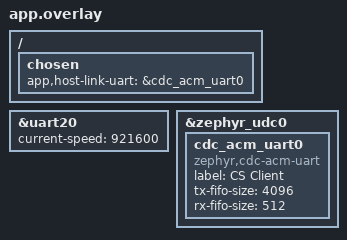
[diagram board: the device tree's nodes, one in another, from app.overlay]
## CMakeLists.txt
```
# SPDX-License-Identifier: MIT

cmake_minimum_required(VERSION 3.20.0)
set(CMAKE_EXPORT_COMPILE_COMMANDS ON)

# Avoid archive failures with the NCS toolchain's ccache link launcher.
set(USE_CCACHE 0)

# One source tree, two builds (README.md): prj.conf is the Bluetooth build,
# -DFILE_SUFFIX=radio_test uses prj_radio_test.conf instead. Both get the shared
# settings; Zephyr merges this with any EXTRA_CONF_FILE given on the command line.
list(APPEND EXTRA_CONF_FILE common.conf)

find_package(Zephyr REQUIRED HINTS $ENV{ZEPHYR_BASE})
project(cs_client)

if(NOT CONFIG_BT)
    set(APP_LIBS_RADIO_TEST ON)
endif()
include(${CMAKE_CURRENT_SOURCE_DIR}/../common/libs/libs.cmake)
target_link_libraries(app PRIVATE app_libs)

target_sources(app PRIVATE
    src/main.c
    src/client_state.c
)

if(CONFIG_BT)
    target_sources(app PRIVATE src/cs_session.c src/peer_discovery.c)
else()
    # The NCS radio test driver is used as-is; its shell front-end is not built.
    target_sources(app PRIVATE
        ${ZEPHYR_NRF_MODULE_DIR}/samples/peripheral/radio_test/src/radio_test.c
        src/radio_session.c
    )
endif()

# Keep the compilation database where clangd discovers it automatically.
add_custom_target(copy_compile_commands ALL
        COMMAND ${CMAKE_COMMAND} -E copy_if_different
                ${CMAKE_BINARY_DIR}/compile_commands.json
                ${CMAKE_CURRENT_SOURCE_DIR}/compile_commands.json
        DEPENDS zephyr_final
        COMMENT "Copying compile_commands.json for clangd"
)

# Export after HEX generation, including builds with no source changes. The
# radio test build (-DFILE_SUFFIX=radio_test) gets its own file name.
if(CONFIG_BUILD_OUTPUT_HEX)
    set(CS_HEX_EXPORT_DIR "${CMAKE_CURRENT_SOURCE_DIR}/../bin")
    set(CS_HEX_EXPORT_NAME "${PROJECT_NAME}")
    if(FILE_SUFFIX)
        string(APPEND CS_HEX_EXPORT_NAME "_${FILE_SUFFIX}")
    endif()
    set(CS_HEX_EXPORT_FILE "${CS_HEX_EXPORT_DIR}/${CS_HEX_EXPORT_NAME}_${BOARD}.hex")
    add_custom_target(cs_export_hex ALL
        COMMAND ${CMAKE_COMMAND} -E make_directory "${CS_HEX_EXPORT_DIR}"
        COMMAND ${CMAKE_COMMAND} -E copy
                "${BYPRODUCT_KERNEL_HEX_NAME}" "${CS_HEX_EXPORT_FILE}"
        DEPENDS "${BYPRODUCT_KERNEL_HEX_NAME}"
        COMMENT "Exporting firmware HEX to ${CS_HEX_EXPORT_FILE}"
        VERBATIM
    )
    add_dependencies(cs_export_hex ${logical_target_for_zephyr_elf})
endif()
```

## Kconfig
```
#
# SPDX-License-Identifier: MIT
#

mainmenu "CS protocol client"

rsource "../common/libs/Kconfig"

# Consumed unconditionally by the NCS radio_test.c in the radio test build,
# which does not build the sample's shell front-end that normally declares it.
config RADIO_TEST_RX_TIMEOUT
	int "RX packet reception timeout"
	depends on !BT
	default 10
	help
	  Time in seconds the driver waits for the first packet in RX mode when a
	  finite packet count is requested. The radio is disabled if it elapses.

config CS_CLIENT_RADIO_TEST_STATS_INTERVAL_MS
	int "RADIO_TEST_STATS report interval in milliseconds"
	depends on !BT
	range 50 10000
	default 250
	help
	  Period of the receive statistics reports while an RX or RX sweep
	  test runs. A baseline follows the START response and a final report
	  precedes the STOPPED state.

source "Kconfig.zephyr"
```

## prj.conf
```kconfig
# Bluetooth build (default): CS initiator and CS reflector in one image, the
# role chosen by the host at runtime, with both Ranging Service roles for
# real-time ranging data. Settings shared with the radio
# test build are in common.conf. Where the NCS ras_initiator and ras_reflector
# samples differ, the larger value is used.

# Host link on native USB CDC ACM (app.overlay), enabled without waiting for a
# host; DTR tracks the host port (CONFIG_APP_HOST_LINK_DTR follows the class).
CONFIG_USB_DEVICE_STACK_NEXT=y
CONFIG_CDC_ACM_SERIAL_INITIALIZE_AT_BOOT=y
CONFIG_CDC_ACM_SERIAL_ENABLE_AT_BOOT=y
CONFIG_CDC_ACM_SERIAL_PRODUCT_STRING="CS Client"
CONFIG_USBD_CDC_ACM_BUF_POOL=y
CONFIG_USBD_CDC_ACM_WORKQUEUE=y

CONFIG_BT=y
CONFIG_BT_DEVICE_NAME="CS Client"
CONFIG_BT_DEVICE_NAME_DYNAMIC=y
CONFIG_BT_DEVICE_NAME_MAX=32
CONFIG_BT_MAX_CONN=1
# GAP role follows the configuration: central scans, peripheral advertises.
CONFIG_BT_CENTRAL=y
CONFIG_BT_PERIPHERAL=y
CONFIG_BT_SMP=y
# Pair for link encryption only; CS security needs no stored bond.
CONFIG_BT_BONDABLE=n
# Connection parameters come from the applied configuration.
CONFIG_BT_GAP_AUTO_UPDATE_CONN_PARAMS=n
CONFIG_BT_GATT_CLIENT=y
# Start the ATT MTU exchange on connection, as cs_hostless_initiator does: without it a
# hosted link stays at the ATT default 23 and the RAS responder segments the ranging data
# into ~39 notifications per procedure instead of 2 (§12.4).
CONFIG_BT_GATT_AUTO_UPDATE_MTU=y
CONFIG_BT_GATT_DYNAMIC_DB=y

CONFIG_BT_CHANNEL_SOUNDING=y
CONFIG_BT_CHANNEL_SOUNDING_TEST=n
# Lets CS and ACL use different PHYs.
CONFIG_BT_TRANSMIT_POWER_CONTROL=y

# The Ranging Profile recommends an ATT MTU of at least 247 octets.
CONFIG_BT_L2CAP_TX_MTU=498
CONFIG_BT_BUF_ACL_TX_SIZE=502
CONFIG_BT_BUF_ACL_RX_SIZE=502
CONFIG_BT_ATT_PREPARE_COUNT=3
CONFIG_BT_CTLR_DATA_LENGTH_MAX=251
CONFIG_BT_CTLR_PHY_2M=y

# Ranging Service: responder (CS reflector role) and requestor (CS initiator role).
CONFIG_BT_RAS=y
CONFIG_BT_RAS_MODE_3_SUPPORTED=y
CONFIG_BT_RAS_MAX_ANTENNA_PATHS=4
CONFIG_BT_RAS_RRSP=y
# The RRSP instance is allocated only in the reflector role.
CONFIG_BT_RAS_RRSP_AUTO_ALLOC_INSTANCE=n
CONFIG_BT_RAS_RRSP_MAX_ACTIVE_CONN=1
CONFIG_BT_RAS_RRSP_RD_BUFFERS_PER_CONN=1
CONFIG_BT_RAS_RREQ=y
CONFIG_BT_RAS_RREQ_MAX_ACTIVE_CONN=1

# SoftDevice Controller with both CS roles, mode 3 and up to 4 antenna paths.
# One local antenna on the DK; the paths come from a multi-antenna peer.
CONFIG_BT_CTLR_CHANNEL_SOUNDING=y
CONFIG_BT_CTLR_CHANNEL_SOUNDING_TEST=n
CONFIG_BT_CTLR_SDC_CS_ROLE_BOTH=y
CONFIG_BT_CTLR_SDC_CS_STEP_MODE3=y
CONFIG_BT_CTLR_SDC_CS_MAX_ANTENNA_PATHS=4
CONFIG_BT_CTLR_SDC_CS_NUM_ANTENNAS=1
# CS enhancements such as IPT need the LL Extended Feature Set.
CONFIG_BT_CTLR_EXTENDED_FEAT_SET=y

# Carry the complete configured name in extended advertising.
CONFIG_BT_EXT_ADV=y
CONFIG_BT_CTLR_ADV_DATA_LEN_MAX=64
CONFIG_BT_EXT_SCAN_BUF_SIZE=1650
# Connection, CS and RAS sequencing in both roles (common/libs/cs_roles).
CONFIG_APP_CS_ROLES=y
CONFIG_APP_CS_ROLES_INITIATOR=y
CONFIG_APP_CS_ROLES_REFLECTOR=y
```

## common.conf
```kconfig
# CS protocol client, settings shared by both builds; CMakeLists.txt adds this
# file to prj.conf or prj_radio_test.conf. Protocol frames on USB CDC ACM
# (Bluetooth build) or uart30 (radio test build), logs on the debug UART. See
# README.md.

CONFIG_APP_HOST_LINK=y
CONFIG_ASSERT=y
CONFIG_MAIN_STACK_SIZE=2048
# State changes raised from work items format their log message on the system work queue.
CONFIG_SYSTEM_WORKQUEUE_STACK_SIZE=2048

# Console on the debug UART; never mixed into the protocol stream. The app_log
# console consumer uses printk, which LOG_PRINTK passes through the deferred
# log with the Zephyr subsystem messages. Levels are set by SET_LOG_CONFIG.
CONFIG_CONSOLE=y
CONFIG_UART_CONSOLE=y
CONFIG_PRINTK=y
CONFIG_LOG=y
CONFIG_LOG_PRINTK=y
CONFIG_LOG_MODE_DEFERRED=y
CONFIG_LOG_PROCESS_THREAD=y
CONFIG_LOG_BUFFER_SIZE=2048
CONFIG_LOG_BACKEND_UART=y
CONFIG_LOG_BACKEND_UART_ASYNC=y
CONFIG_LOG_BACKEND_UART_BUFFER_SIZE=256

# The host link UART needs the interrupt API, but uart20 uses asynchronous UARTE DMA.
CONFIG_UART_ASYNC_API=y
CONFIG_UART_20_INTERRUPT_DRIVEN=n
CONFIG_UART_20_ASYNC=y
CONFIG_BOOT_BANNER=n
```

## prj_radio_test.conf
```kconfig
# Radio test build: direct radio access, no Bluetooth stack and no MPSL.
# Used instead of prj.conf with -DFILE_SUFFIX=radio_test; settings shared with
# the Bluetooth build are in common.conf. See README.md.
CONFIG_BT=n

# Host link on uart30 (app_radio_test.overlay), not USB: no USB device stack.
# A hardware UART has no DTR, so a host session ends only with CLOSE_SESSION.
CONFIG_UART_30_INTERRUPT_DRIVEN=y

CONFIG_DYNAMIC_INTERRUPTS=y
CONFIG_NRFX_TIMER=y
CONFIG_NRFX_GPPI=y
CONFIG_CLOCK_CONTROL=y

# radio_test.c seeds its transmit pattern from the entropy driver.
CONFIG_ENTROPY_GENERATOR=y
CONFIG_PSA_CRYPTO=y

# Provides <fem_al/fem_al.h>, which radio_test.h includes unconditionally.
# CONFIG_FEM stays off on a bare DK, so no FEM code is built.
CONFIG_FEM_AL_LIB=y
```

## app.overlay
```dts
/* SPDX-License-Identifier: MIT */
/ {
	chosen {
		app,host-link-uart = &cdc_acm_uart0;
	};
};

&uart20 {
	current-speed = <921600>;
};

&zephyr_udc0 {
	status = "okay";

	cdc_acm_uart0: cdc_acm_uart0 {
		compatible = "zephyr,cdc-acm-uart";
		label = "CS Client";
		tx-fifo-size = <4096>;
		rx-fifo-size = <512>;
	};
};
```

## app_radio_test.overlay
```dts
/* SPDX-License-Identifier: MIT */
/* Radio test build (-DFILE_SUFFIX=radio_test, used instead of app.overlay):
 * protocol frames on uart30, the DK's second virtual COM port, so the build
 * needs no USB device controller. Logs stay on uart20.
 */
/ {
	chosen {
		app,host-link-uart = &uart30;
	};
};

&uart20 {
	current-speed = <921600>;
};

&uart30 {
	status = "okay";
	current-speed = <921600>;
	hw-flow-control;
};
```

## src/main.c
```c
/* SPDX-License-Identifier: MIT */
#include <app_version.h>
#include <zephyr/kernel.h>

#include "app_log/app_log.h"
#include "host_link/host_link.h"
#include "session.h"

APP_LOG_MODULE(cs_client);

int main(void) {
	int err;

	APP_LOG_INF("CS client %s, %s build", APP_VERSION_STRING, session_build_name());

	/* Boots to IDLE: no radio activity before APPLY_CONFIG and START. */
	err = session_init();
	if (err) {
		APP_LOG_ERR("Session init failed: %d", err);
		return 0;
	}

	err = host_link_init(session_handlers());
	if (err) {
		APP_LOG_ERR("Host link init failed: %d", err);
		return 0;
	}
	APP_LOG_INF("Waiting for the host on USB CDC ACM");
	return 0;
}
```

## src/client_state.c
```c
/* SPDX-License-Identifier: MIT */
#include <zephyr/kernel.h>

#include "app_log/app_log.h"
#include "client_state.h"
#include "cs_protocol/cs_protocol_packets.h"
#include "host_link/host_link_names.h"
#include "host_link/host_link_reports.h"

APP_LOG_MODULE(client_state);

static K_MUTEX_DEFINE(lock);
static uint8_t state = CS_PROTOCOL_CLIENT_STATE_IDLE;
static uint8_t mode = CS_PROTOCOL_MODE_NONE;

/* Last change with an error the host has not received, sent after the next CONNECT. */
static struct {
	bool pending;
	uint8_t state;
	uint8_t mode;
	uint8_t reason;
	uint8_t hci_status;
	int32_t error;
} undelivered;

uint8_t client_state_get(void) {
	uint8_t value;

	k_mutex_lock(&lock, K_FOREVER);
	value = state;
	k_mutex_unlock(&lock);
	return value;
}

uint8_t client_state_mode(void) {
	uint8_t value;

	k_mutex_lock(&lock, K_FOREVER);
	value = mode;
	k_mutex_unlock(&lock);
	return value;
}

void client_state_set_mode(uint8_t new_mode) {
	k_mutex_lock(&lock, K_FOREVER);
	mode = new_mode;
	k_mutex_unlock(&lock);
}

/* States the host should treat as abnormal. */
static bool is_abnormal(uint8_t value, int32_t error) {
	return value == CS_PROTOCOL_CLIENT_STATE_LINK_LOST || value == CS_PROTOCOL_CLIENT_STATE_ERROR ||
	       error != 0;
}

/* Called with the lock held. */
static void set_locked(uint8_t new_state, uint8_t reason, uint8_t hci_status, int32_t error) {
	uint8_t old_state = state;
	int err;

	state = new_state;
	/* Without a host session the report is dropped and CONNECT reports the state;
	 * an error is kept so the host still learns why the operation ended.
	 */
	err = host_link_report_client_state(new_state, mode, reason, hci_status, error);
	if (error != 0) {
		undelivered.pending = err != 0;
		undelivered.state = new_state;
		undelivered.mode = mode;
		undelivered.reason = reason;
		undelivered.hci_status = hci_status;
		undelivered.error = error;
	} else if (err == 0) {
		/* The host has seen a newer state; an older interruption is stale. */
		undelivered.pending = false;
	}
	if (is_abnormal(new_state, error)) {
		APP_LOG_WRN("State %s -> %s, mode %s, reason %s, HCI status 0x%02x, error %d",
		            host_link_state_name(old_state), host_link_state_name(new_state),
		            host_link_mode_name(mode), host_link_reason_name(reason), hci_status,
		            (int)error);
	} else {
		APP_LOG_INF("State %s -> %s, mode %s, reason %s, HCI status 0x%02x",
		            host_link_state_name(old_state), host_link_state_name(new_state),
		            host_link_mode_name(mode), host_link_reason_name(reason), hci_status);
	}
}

void client_state_set(uint8_t new_state, uint8_t reason, uint8_t hci_status, int32_t error) {
	k_mutex_lock(&lock, K_FOREVER);
	set_locked(new_state, reason, hci_status, error);
	k_mutex_unlock(&lock);
}

bool client_state_change(uint8_t from, uint8_t to, uint8_t reason, int32_t error) {
	bool changed;

	k_mutex_lock(&lock, K_FOREVER);
	changed = state == from;
	if (changed) {
		set_locked(to, reason, 0U, error);
	}
	k_mutex_unlock(&lock);
	return changed;
}

void client_state_session_changed(bool active) {
	if (!active) {
		/* State and mode describe the device, not the host connection. */
		return;
	}
	k_mutex_lock(&lock, K_FOREVER);
	if (undelivered.pending &&
	    host_link_report_client_state(undelivered.state, undelivered.mode, undelivered.reason,
	                                  undelivered.hci_status, undelivered.error) == 0) {
		undelivered.pending = false;
		APP_LOG_WRN("Reported earlier state %s, reason %s, error %d",
		            host_link_state_name(undelivered.state),
		            host_link_reason_name(undelivered.reason), (int)undelivered.error);
	}
	k_mutex_unlock(&lock);
}
```

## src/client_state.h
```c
/* SPDX-License-Identifier: MIT */
#ifndef CLIENT_STATE_H_
#define CLIENT_STATE_H_

#include <stdbool.h>
#include <stdint.h>

/**
 * @file
 * @brief Client state and applied operation mode, reported as CLIENT_STATE.
 *
 * Thread context only. Every change is reported to the host while holding the
 * state lock, so the host sees changes in the order they happened: a
 * CLIENT_STATE frame followed by a LOG_MESSAGE naming the old and new state
 * (level warning for LINK_LOST, ERROR and any change with an error).
 *
 * A change with a non-zero error that could not be reported (no host session)
 * is reported again when the next session opens, unless the host has seen a
 * newer state in between.
 */

/** @brief Current @ref cs_protocol_client_state. */
uint8_t client_state_get(void);

/** @brief Applied operation mode, or @ref CS_PROTOCOL_MODE_NONE. */
uint8_t client_state_mode(void);

/** @brief Record the applied operation mode; no report. */
void client_state_set_mode(uint8_t mode);

/**
 * @brief Change the state and report it.
 *
 * @param state      One of @ref cs_protocol_client_state.
 * @param reason     One of @ref cs_protocol_reject_reason.
 * @param hci_status HCI status behind the change; 0 when none.
 * @param error      Negative errno when an operation ended abnormally; 0 otherwise.
 */
void client_state_set(uint8_t state, uint8_t reason, uint8_t hci_status, int32_t error);

/**
 * @brief Change the state and report it only if it is still @p from.
 * @return True when the state changed.
 */
bool client_state_change(uint8_t from, uint8_t to, uint8_t reason, int32_t error);

/**
 * @brief host_link session_changed handler: on open, report an undelivered
 * change with an error; ending a session preserves device state and mode.
 */
void client_state_session_changed(bool active);

#endif /* CLIENT_STATE_H_ */
```

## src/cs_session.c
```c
/* SPDX-License-Identifier: MIT */
/* Bluetooth build: host link handlers -> CS initiator / reflector roles. */
#include <app_version.h>
#include <errno.h>
#include <string.h>
#include <zephyr/bluetooth/bluetooth.h>
#include <zephyr/kernel.h>

#include "app_log/app_log.h"
#include "client_state.h"
#include "cs_roles/cs_role.h"
#include "cs_utils/cs_config.h"
#include "host_link/host_link.h"
#include "host_link/host_link_config.h"
#include "host_link/host_link_reports.h"
#include "peer_discovery.h"
#include "session.h"

APP_LOG_MODULE(cs_session);

/* Records of the applied configuration, converted with the cs_utils setters. */
static struct cs_initiator_config initiator;
static struct cs_reflector_config reflector;
static uint8_t gap_role;

/* The link layer owns the negotiated values; retain the latest snapshot so a
 * host that opens USB after Bluetooth connection setup still receives them. */
static struct k_spinlock connection_params_lock;
static struct cs_config_connection connection_params;
static uint16_t connection_mtu;
static bool connection_params_valid;

static void report_connection_params_work(struct k_work *work);
static K_WORK_DEFINE(connection_params_report_work,
                     report_connection_params_work);

static void role_connection_params(const struct cs_config_connection *params,
                                   uint16_t mtu) {
	if (!params) {
		return;
	}
	K_SPINLOCK(&connection_params_lock) {
		connection_params = *params;
		connection_mtu = mtu;
		connection_params_valid = true;
	}
	(void)k_work_submit(&connection_params_report_work);
}

static void report_connection_params_work(struct k_work *work) {
	struct cs_config_connection params;
	uint16_t mtu = 0;
	bool valid = false;

	ARG_UNUSED(work);
	if (!host_link_session_active()) {
		return;
	}
	K_SPINLOCK(&connection_params_lock) {
		params = connection_params;
		mtu = connection_mtu;
		valid = connection_params_valid;
	}
	if (valid) {
		(void)host_link_report_connection_parameters(params.interval_min,
		                                             params.latency,
		                                             params.timeout,
		                                             mtu);
	}
}

static uint8_t get_state(void) {
	return client_state_get();
}

/* Discovery and connection establishment are separate from CS START. */
static bool link_active(void) {
	return peer_discovery_active();
}

static const char *peer_data_name(uint8_t peer_data) {
	return peer_data == CS_CONFIG_PEER_DATA_NONE ? "none (initiator only)" : "RAS real-time";
}

static int convert(uint8_t mode,
                   const uint8_t *payload,
                   size_t len,
                   struct cs_initiator_config *initiator_out,
                   struct cs_reflector_config *reflector_out) {
	switch (mode) {
	case CS_PROTOCOL_MODE_CS_INITIATOR:
		return host_link_config_to_initiator(payload, len, initiator_out);
	case CS_PROTOCOL_MODE_CS_REFLECTOR:
		return host_link_config_to_reflector(payload, len, reflector_out);
	default:
		return -ENOTSUP;
	}
}

static struct host_link_result validate_config(uint8_t mode,
                                               const uint8_t *payload,
                                               size_t len) {
	struct cs_initiator_config initiator_check;
	struct cs_reflector_config reflector_check;
	int err = convert(mode, payload, len, &initiator_check, &reflector_check);

	if (err == -ENOTSUP) {
		return HOST_LINK_RESULT(CS_PROTOCOL_STATUS_UNSUPPORTED, CS_PROTOCOL_REASON_NONE);
	}
	return err ? HOST_LINK_RESULT_OUT_OF_RANGE(err) : HOST_LINK_RESULT_OK;
}

static struct host_link_result apply(const struct host_link_config_set *set) {
	struct cs_initiator_config initiator_new;
	struct cs_reflector_config reflector_new;
	/* The initiator record also takes SET_PEER_DATA, checked against the IPT request. */
	int err = set->mode == CS_PROTOCOL_MODE_CS_INITIATOR
	                  ? host_link_config_set_to_initiator(set, &initiator_new)
	                  : convert(set->mode, set->config, set->config_len, &initiator_new, &reflector_new);

	if (err) {
		return HOST_LINK_RESULT_OUT_OF_RANGE(err);
	}
	char device_name[33] = CONFIG_BT_DEVICE_NAME;
	if (set->has_device_name) {
		memcpy(device_name, &set->device_name[1], set->device_name[0]);
		device_name[set->device_name[0]] = '\0';
	}
	err = bt_set_name(device_name);
	if (err) {
		return HOST_LINK_RESULT_FAILED(err);
	}
	if (set->mode == CS_PROTOCOL_MODE_CS_INITIATOR) {
		initiator = initiator_new;
	} else {
		reflector = reflector_new;
	}
	gap_role = host_link_config_gap_role(set->config);
	peer_discovery_configure(gap_role,
	                         set->mode,
	                         set->mode == CS_PROTOCOL_MODE_CS_INITIATOR ? &initiator.connection
	                                                                    : &reflector.connection);

	APP_LOG_INF("CS %s, GAP %s, config ID %u%s",
	            set->mode == CS_PROTOCOL_MODE_CS_INITIATOR ? "initiator" : "reflector",
	            gap_role == CS_PROTOCOL_GAP_CENTRAL ? "central" : "peripheral",
	            set->mode == CS_PROTOCOL_MODE_CS_INITIATOR ? initiator.config_id : reflector.config_id,
	            set->has_patterns ? ", with peripheral patterns" : "");
	if (set->mode == CS_PROTOCOL_MODE_CS_INITIATOR) {
		APP_LOG_INF("Reflector data: %s, preferred T_PM %u us",
		            peer_data_name(initiator.peer_data),
		            initiator.t_pm_us);
	}
	client_state_set_mode(set->mode);
	client_state_set(CS_PROTOCOL_CLIENT_STATE_CONFIGURED, CS_PROTOCOL_REASON_NONE, 0U, 0);
	return HOST_LINK_RESULT_OK;
}

static struct host_link_result start(const struct host_link_config_set *set) {
	ARG_UNUSED(set);
	int err = client_state_mode() == CS_PROTOCOL_MODE_CS_INITIATOR ? cs_role_start_initiator(&initiator)
	                                                               : cs_role_start_reflector(&reflector);
	if (err == -ENOTCONN) {
		return HOST_LINK_RESULT(CS_PROTOCOL_STATUS_BAD_STATE, CS_PROTOCOL_REASON_CONNECT_FAILED);
	}
	return err ? HOST_LINK_RESULT_FAILED(err) : HOST_LINK_RESULT_OK;
}

/* STOP disables procedures and keeps the link. The initiator also waits for the
 * reflector's data of the last procedure: when it does not arrive, RAS_DATA_LOST
 * has been sent and the response is OK with CS_PROTOCOL_REASON_STOP_TIMEOUT.
 * The host link also calls this at session end: it cancels discovery or a CS
 * setup, and does nothing on an idle link. The role and event threads run above
 * the host link thread, so the STOPPED report of a cancelled setup has been
 * attempted, and kept for the next session, by the time cs_role_stop() returns.
 */
static struct host_link_result stop(void) {
	if (client_state_get() == CS_PROTOCOL_CLIENT_STATE_SCANNING ||
	    client_state_get() == CS_PROTOCOL_CLIENT_STATE_ADVERTISING ||
	    client_state_get() == CS_PROTOCOL_CLIENT_STATE_LINK_CONNECTING) {
		return peer_discovery_stop();
	}
	int err = cs_role_stop();
	if (err == -ETIMEDOUT) {
		return (struct host_link_result){ CS_PROTOCOL_STATUS_OK, CS_PROTOCOL_REASON_STOP_TIMEOUT, err };
	}
	return err ? HOST_LINK_RESULT_FAILED(err) : HOST_LINK_RESULT_OK;
}

static void interrupt(int error) {
	cs_role_interrupt(error);
}

/* Also called while RUNNING: procedures are stopped first, reported as a STOP. */
static struct host_link_result link_disconnect(void) {
	int err = cs_role_stop();
	if (err && err != -ETIMEDOUT && err != -ENOTCONN) {
		return HOST_LINK_RESULT_FAILED(err);
	}
	return peer_discovery_stop();
}

static uint8_t failure_reason(enum cs_role_failure_stage stage) {
	switch (stage) {
	case CS_ROLE_FAILURE_CONNECT:
		return CS_PROTOCOL_REASON_CONNECT_FAILED;
	case CS_ROLE_FAILURE_LINK_SECURITY:
		return CS_PROTOCOL_REASON_SECURITY_FAILED;
	case CS_ROLE_FAILURE_RAS_DISCOVERY:
		return CS_PROTOCOL_REASON_RAS_DISCOVERY_FAILED;
	case CS_ROLE_FAILURE_RAS_NO_REALTIME:
		return CS_PROTOCOL_REASON_RAS_NO_REALTIME;
	case CS_ROLE_FAILURE_SECURITY:
		return CS_PROTOCOL_REASON_CS_SECURITY_FAILED;
	case CS_ROLE_FAILURE_CAPABILITIES:
	case CS_ROLE_FAILURE_CONFIG:
	case CS_ROLE_FAILURE_PROCEDURE:
	case CS_ROLE_FAILURE_PEER_ANTENNA:
		return CS_PROTOCOL_REASON_CS_CONFIG_FAILED;
	case CS_ROLE_FAILURE_PEER_IPT:
		return CS_PROTOCOL_REASON_PEER_IPT_UNSUPPORTED;
	default:
		return CS_PROTOCOL_REASON_NONE;
	}
}

static void role_state(enum cs_role_state state,
                       enum cs_role_failure_stage stage,
                       enum cs_role_stop_reason stop_reason,
                       uint8_t hci_status,
                       int error) {
	switch (state) {
	case CS_ROLE_STATE_LINK_CONNECTED:
		client_state_set(CS_PROTOCOL_CLIENT_STATE_LINK_CONNECTED, CS_PROTOCOL_REASON_NONE, 0, 0);
		break;
	case CS_ROLE_STATE_LINK_ENCRYPTED:
		APP_LOG_INF("Peer link encrypted");
		break;
	case CS_ROLE_STATE_LINK_LOST:
		K_SPINLOCK(&connection_params_lock) {
			connection_params_valid = false;
		}
		client_state_set(CS_PROTOCOL_CLIENT_STATE_LINK_LOST,
		                 CS_PROTOCOL_REASON_INTERRUPTED,
		                 hci_status,
		                 error);
		break;
	case CS_ROLE_STATE_LINK_DISCONNECTED:
		K_SPINLOCK(&connection_params_lock) {
			connection_params_valid = false;
		}
		/* peer_discovery.c reports the protocol state for this transition. */
		break;
	case CS_ROLE_STATE_RAS_READY:
		client_state_set(CS_PROTOCOL_CLIENT_STATE_RAS_READY, CS_PROTOCOL_REASON_NONE, 0, 0);
		break;
	case CS_ROLE_STATE_RUNNING:
		client_state_set(CS_PROTOCOL_CLIENT_STATE_RUNNING, CS_PROTOCOL_REASON_NONE, 0, 0);
		break;
	case CS_ROLE_STATE_STOPPED:
		if (stop_reason == CS_ROLE_STOP_COMPLETE) {
			client_state_set(CS_PROTOCOL_CLIENT_STATE_STOPPED,
			                 CS_PROTOCOL_REASON_TEST_COMPLETE,
			                 hci_status,
			                 0);
		} else {
			/* HOST: -ECANCELED. PEER: the initiator stopped this reflector,
			 * reported as -ECONNABORTED. INTERRUPTED and LINK_LOST carry their error.
			 */
			client_state_set(CS_PROTOCOL_CLIENT_STATE_STOPPED,
			                 CS_PROTOCOL_REASON_INTERRUPTED,
			                 hci_status,
			                 stop_reason == CS_ROLE_STOP_PEER ? -ECONNABORTED
			                 : error                          ? error
			                                                  : -ECANCELED);
		}
		break;
	case CS_ROLE_STATE_ERROR:
		client_state_set(CS_PROTOCOL_CLIENT_STATE_ERROR, failure_reason(stage), hci_status, error);
		break;
	default:
		/* SCANNING, ADVERTISING, LINK_CONNECTING and LINK_DISCONNECTED follow
		 * host commands; peer_discovery.c reports them with the response. */
		break;
	}
}

static void role_capabilities(const struct cs_capabilities *record) {
	(void)host_link_report_cs_capabilities(record);
}
/* The initiator follows the configuration with its reflector data setting,
 * before the first subevent: the controller's report does not carry it.
 */
static void role_configuration(const struct cs_config_complete *record) {
	(void)host_link_report_cs_configuration(record);
	if (client_state_mode() == CS_PROTOCOL_MODE_CS_INITIATOR && record->status == 0U) {
		(void)host_link_report_peer_data(initiator.peer_data);
	}
}
static void role_procedure(const struct cs_procedure_enable_complete *record) {
	(void)host_link_report_cs_procedure(record);
}
/* Subevents are encoded straight into the transmit buffer (Bluetooth context). */
static int role_subevent_begin(const struct cs_subevent *header,
                               uint16_t num_tones) {
	return host_link_report_cs_subevent_begin(header, num_tones);
}
static void role_subevent_step(const struct cs_step_header *step) {
	host_link_report_cs_subevent_step(step);
}
static void role_subevent_end(bool complete) {
	ARG_UNUSED(complete);
	(void)host_link_report_cs_subevent_end();
}
static void role_fae(uint8_t status,
                     uint8_t lsb_denominator,
                     const int8_t *entries) {
	(void)host_link_report_fae_table(status, entries, lsb_denominator);
}
static void role_ras_lost(uint16_t counter,
                          int error) {
	(void)host_link_report_ras_data_lost(counter, error);
}
/* Precedes STOPPED(COMPLETE), which reports CLIENT_STATE(STOPPED, TEST_COMPLETE). */
static void role_procedures_complete(uint16_t procedures_completed) {
	(void)host_link_report_cs_procedures_complete(procedures_completed);
}

static const struct cs_role_callbacks role_callbacks = {
	.state = role_state,
	.connection_params = role_connection_params,
	.scan_result = peer_discovery_scan_result,
	.capabilities = role_capabilities,
	.configuration = role_configuration,
	.procedure = role_procedure,
	.subevent_begin = role_subevent_begin,
	.subevent_step = role_subevent_step,
	.subevent_end = role_subevent_end,
	.fae_table = role_fae,
	.ras_data_lost = role_ras_lost,
	.procedures_complete = role_procedures_complete,
};

/* Applied configuration and an established Bluetooth link span host sessions. */
static void session_changed(bool active) {
	client_state_session_changed(active);
	if (active) {
		/* Runs after CONNECT_RESPONSE, so the report follows the handshake. */
		(void)k_work_submit(&connection_params_report_work);
	}
}

static const struct host_link_handlers handlers = {
	.supported_modes = CS_PROTOCOL_MODE_BIT(CS_PROTOCOL_MODE_CS_INITIATOR) |
	                   CS_PROTOCOL_MODE_BIT(CS_PROTOCOL_MODE_CS_REFLECTOR),
	.firmware_version = APPVERSION,
	.client_state = get_state,
	.link_active = link_active,
	.discovery = peer_discovery_command,
	.validate_config = validate_config,
	.apply = apply,
	.start = start,
	.stop = stop,
	.interrupt = interrupt,
	.link_disconnect = link_disconnect,
	.session_changed = session_changed,
};

int session_init(void) {
	/* Enabling the stack starts no scanning or advertising. */
	int err = bt_enable(NULL);
	if (!err) {
		err = cs_role_init(&role_callbacks);
	}
	return err;
}

const struct host_link_handlers *session_handlers(void) {
	return &handlers;
}

const char *session_build_name(void) {
	return "Bluetooth";
}
```

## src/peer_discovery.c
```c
/* SPDX-License-Identifier: MIT */
/* Discovery and link commands -> cs_role_link_*; scan reports -> SCAN_RESULT frames. */
#include <errno.h>
#include <string.h>
#include <zephyr/kernel.h>
#include <zephyr/bluetooth/addr.h>
#include <zephyr/sys/atomic.h>
#include "app_log/app_log.h"
#include "cs_utils/cs_config.h"
#include "host_link/host_link_reports.h"
#include "cs_protocol/cs_protocol.h"
#include "client_state.h"
#include "cs_roles/cs_role.h"
#include "peer_discovery.h"

APP_LOG_MODULE(peer_discovery);

/* Never block the Bluetooth receive thread on serial backpressure. */
K_MSGQ_DEFINE(scan_reports, sizeof(struct cs_protocol_scan_result_frame_t), 32, 4);
static atomic_t scan_dropped;
static atomic_t discovering;

static void report_scans(void *a, void *b, void *c) {
    ARG_UNUSED(a); ARG_UNUSED(b); ARG_UNUSED(c);
    struct cs_protocol_scan_result_frame_t frame;
    for (;;) {
        k_msgq_get(&scan_reports, &frame, K_FOREVER);
        if (!atomic_get(&discovering)) {
            continue;
        }
        cs_protocol_finalize_frame(&frame, sizeof(frame), CS_PROTOCOL_PACKET_SCAN_RESULT);
        host_link_report_frame((const uint8_t *)&frame, sizeof(frame));
        atomic_val_t dropped = atomic_clear(&scan_dropped);
        if (dropped) {
            APP_LOG_WRN("%ld scan reports dropped: queue full", (long)dropped);
        }
    }
}
K_THREAD_DEFINE(scan_report_thread, 1536, report_scans, NULL, NULL, NULL, 7, 0, 0);

static uint8_t gap_role;
static uint8_t operation_mode;
static struct cs_config_connection connection_params;

bool peer_discovery_active(void) {
    return cs_role_link_active();
}

void peer_discovery_configure(uint8_t role, uint8_t mode,
                              const struct cs_config_connection *params) {
    gap_role = role;
    operation_mode = mode;
    connection_params = *params;
}

static struct host_link_result failure(uint8_t reason, int err) {
    client_state_set(CS_PROTOCOL_CLIENT_STATE_ERROR, reason, 0, err);
    return (struct host_link_result){CS_PROTOCOL_STATUS_FAILED, reason, err};
}

/* Bluetooth context (cs_roles scan_result callback). */
void peer_discovery_scan_result(const struct cs_role_scan_result *result) {
    struct cs_protocol_scan_result_frame_t frame = {
        .address_type = result->address.type,
        .rssi_dbm = result->rssi,
        .flags = result->connectable ? 1 : 0,
    };

    if (!atomic_get(&discovering) || result->address.type > BT_ADDR_LE_RANDOM) {
        return;
    }
    memcpy(frame.address, result->address.a.val, sizeof(frame.address));
    if (result->name_len) {
        frame.name_length = MIN(result->name_len, sizeof(frame.name));
        memcpy(frame.name, result->name, frame.name_length);
        frame.flags |= result->name_complete ? 2 : 0;
    }
    if (k_msgq_put(&scan_reports, &frame, K_NO_WAIT)) {
        atomic_inc(&scan_dropped);
    }
}

struct host_link_result peer_discovery_command(uint16_t type, const uint8_t *payload) {
    bool central = type != CS_PROTOCOL_PACKET_ADVERTISE_START;
    int err;

    if ((central && gap_role != CS_PROTOCOL_GAP_CENTRAL) ||
        (!central && gap_role == CS_PROTOCOL_GAP_CENTRAL)) {
        return HOST_LINK_RESULT(CS_PROTOCOL_STATUS_BAD_STATE, CS_PROTOCOL_REASON_MODE_MISMATCH);
    }
    if (cs_role_link_active() &&
        !(atomic_get(&discovering) && type == CS_PROTOCOL_PACKET_PEER_CONNECT)) {
        return HOST_LINK_RESULT(CS_PROTOCOL_STATUS_BAD_STATE, CS_PROTOCOL_REASON_LINK_ACTIVE);
    }
    if (type == CS_PROTOCOL_PACKET_PEER_CONNECT && payload[0] > BT_ADDR_LE_RANDOM) {
        return HOST_LINK_RESULT_OUT_OF_RANGE(-EINVAL);
    }
    if (type == CS_PROTOCOL_PACKET_SCAN_START) {
        /* Active scanning, no filtering: the host filters by name pattern
         * and can still show every peer. */
        k_msgq_purge(&scan_reports);
        atomic_clear(&scan_dropped);
        atomic_set(&discovering, 1);
        err = cs_role_scan_start();
        if (err) {
            atomic_clear(&discovering);
            return failure(CS_PROTOCOL_REASON_SCAN_FAILED, err);
        }
        client_state_set(CS_PROTOCOL_CLIENT_STATE_SCANNING, CS_PROTOCOL_REASON_NONE, 0, 0);
        return HOST_LINK_RESULT_OK;
    }

    bt_addr_le_t addr = {.type = payload ? payload[0] : 0};
    struct cs_role_link_params params = {
        .central = central,
        .connection = connection_params,
        /* Reflector advertisements carry the Ranging Service UUID. */
        .advertise_ras_uuid = operation_mode == CS_PROTOCOL_MODE_CS_REFLECTOR,
    };

    if (central) {
        memcpy(addr.a.val, payload + 1, sizeof(addr.a.val));
        params.peer = &addr;
    }
    atomic_clear(&discovering);
    err = cs_role_link_start(&params);
    if (err) {
        return failure(central ? CS_PROTOCOL_REASON_CONNECT_FAILED :
                                 CS_PROTOCOL_REASON_ADVERTISE_FAILED, err);
    }
    client_state_set(central ? CS_PROTOCOL_CLIENT_STATE_LINK_CONNECTING :
                               CS_PROTOCOL_CLIENT_STATE_ADVERTISING,
                     CS_PROTOCOL_REASON_NONE, 0, 0);
    return HOST_LINK_RESULT_OK;
}

struct host_link_result peer_discovery_stop(void) {
    atomic_clear(&discovering);
    int err = cs_role_link_disconnect(K_SECONDS(3));

    if (err) {
        return failure(CS_PROTOCOL_REASON_CONNECT_FAILED, err);
    }
    client_state_set(CS_PROTOCOL_CLIENT_STATE_LINK_DISCONNECTED, CS_PROTOCOL_REASON_NONE, 0, 0);
    return HOST_LINK_RESULT_OK;
}
```

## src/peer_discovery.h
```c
/* SPDX-License-Identifier: MIT */
#ifndef PEER_DISCOVERY_H_
#define PEER_DISCOVERY_H_
#include "cs_utils/cs_config.h"
#include "host_link/host_link_types.h"
struct cs_role_scan_result;
bool peer_discovery_active(void);
void peer_discovery_configure(uint8_t role, uint8_t operation_mode,
                              const struct cs_config_connection *params);
/** cs_role_callbacks.scan_result: queue a SCAN_RESULT frame (Bluetooth context). */
void peer_discovery_scan_result(const struct cs_role_scan_result *result);
struct host_link_result peer_discovery_command(uint16_t type, const uint8_t *payload);
struct host_link_result peer_discovery_stop(void);
#endif
```

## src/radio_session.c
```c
/* SPDX-License-Identifier: MIT */
/* Radio test build: host link handlers -> radio_test_utils. */
#include <app_version.h>
#include <errno.h>
#include <zephyr/kernel.h>

#include "app_log/app_log.h"
#include "client_state.h"
#include "host_link/host_link_config.h"
#include "host_link/host_link_reports.h"
#include "radio_test_utils/radio_test_mode.h"
#include "session.h"

APP_LOG_MODULE(radio_session);

/* The radio test driver drives RADIO, TIMER10 and EGU10 directly. MPSL claims
 * the same peripherals on the nRF54L series, so this build has no Bluetooth.
 */
BUILD_ASSERT(!IS_ENABLED(CONFIG_BT),
             "The radio test driver cannot share the radio with the Bluetooth stack");

/* The applied test ends on its own after a finite packet count. */
static bool finite_test;
/* The applied test receives (RX or RX sweep) and reports RADIO_TEST_STATS. */
static bool rx_test;

/* RADIO_TEST_STATS: a baseline after the START response, periodic reports,
 * and a final report before the test's STOPPED state. stats_active is set
 * from START until the final report, so a STOP racing a completion reports
 * once.
 */
static K_MUTEX_DEFINE(stats_lock);
static bool stats_active;

static void stats_work_handler(struct k_work *work);
static K_WORK_DELAYABLE_DEFINE(stats_work, stats_work_handler);

/* Called with stats_lock held. */
static void stats_send(void) {
	struct radio_test_mode_rx_stats stats;

	if (radio_test_mode_rx_stats_get(&stats) == 0) {
		(void)host_link_report_radio_test_stats(stats.packets_received, stats.crc_errors,
		                                        stats.rssi_dbm, stats.channel);
	}
}

static void stats_work_handler(struct k_work *work) {
	ARG_UNUSED(work);
	k_mutex_lock(&stats_lock, K_FOREVER);
	if (stats_active) {
		stats_send();
		(void)k_work_schedule(&stats_work, K_MSEC(CONFIG_CS_CLIENT_RADIO_TEST_STATS_INTERVAL_MS));
	}
	k_mutex_unlock(&stats_lock);
}

/* Final report of an RX test; call once the radio has stopped. */
static void stats_finish(void) {
	k_mutex_lock(&stats_lock, K_FOREVER);
	if (stats_active) {
		stats_active = false;
		stats_send();
	}
	k_mutex_unlock(&stats_lock);
	/* A handler already running finds stats_active cleared. */
	(void)k_work_cancel_delayable(&stats_work);
}

static void test_complete_work_handler(struct k_work *work) {
	ARG_UNUSED(work);
	stats_finish();
	/* A STOP that raced the completion has already reported STOPPED. */
	if (client_state_change(CS_PROTOCOL_CLIENT_STATE_RUNNING, CS_PROTOCOL_CLIENT_STATE_STOPPED,
	                        CS_PROTOCOL_REASON_TEST_COMPLETE, 0)) {
		APP_LOG_INF("Radio test complete");
	}
}

static K_WORK_DEFINE(test_complete_work, test_complete_work_handler);

/* Interrupt or system work queue context: hand over to a thread. */
static void test_done(void) {
	(void)k_work_submit(&test_complete_work);
}

static uint8_t get_state(void) {
	return client_state_get();
}

static bool link_active(void) {
	return false;
}

static struct host_link_result validate_config(uint8_t mode, const uint8_t *payload, size_t len) {
	struct radio_test_mode_config config;
	int err;

	if (mode != CS_PROTOCOL_MODE_RADIO_TX_TEST) {
		return HOST_LINK_RESULT(CS_PROTOCOL_STATUS_UNSUPPORTED, CS_PROTOCOL_REASON_NONE);
	}
	err = host_link_config_to_radio_test(payload, len, &config);
	return err ? HOST_LINK_RESULT_OUT_OF_RANGE(err) : HOST_LINK_RESULT_OK;
}

static struct host_link_result apply(const struct host_link_config_set *set) {
	struct radio_test_mode_config config;
	int err;

	err = host_link_config_to_radio_test(set->config, set->config_len, &config);
	if (err) {
		return HOST_LINK_RESULT_OUT_OF_RANGE(err);
	}
	config.done_cb = test_done;
	err = radio_test_mode_apply(&config);
	if (err) {
		return HOST_LINK_RESULT_FAILED(err);
	}
	finite_test = config.packet_count != 0U;
	rx_test = config.type == RADIO_TEST_MODE_RX || config.type == RADIO_TEST_MODE_RX_SWEEP;
	client_state_set_mode(set->mode);
	client_state_set(CS_PROTOCOL_CLIENT_STATE_CONFIGURED, CS_PROTOCOL_REASON_NONE, 0U, 0);
	return HOST_LINK_RESULT_OK;
}

static struct host_link_result start(const struct host_link_config_set *set) {
	int err;

	ARG_UNUSED(set);
	err = radio_test_mode_start();
	if (err) {
		return HOST_LINK_RESULT_FAILED(err);
	}
	k_mutex_lock(&stats_lock, K_FOREVER);
	stats_active = rx_test;
	k_mutex_unlock(&stats_lock);
	client_state_set(CS_PROTOCOL_CLIENT_STATE_RUNNING, CS_PROTOCOL_REASON_NONE, 0U, 0);
	return HOST_LINK_RESULT_OK;
}

/* The RX statistics baseline follows the START response. */
static void response_sent(uint16_t request_type, struct host_link_result result) {
	if (request_type != CS_PROTOCOL_PACKET_START || result.status != CS_PROTOCOL_STATUS_OK) {
		return;
	}
	k_mutex_lock(&stats_lock, K_FOREVER);
	/* Not active when a short finite test already completed. */
	if (stats_active) {
		stats_send();
		(void)k_work_schedule(&stats_work, K_MSEC(CONFIG_CS_CLIENT_RADIO_TEST_STATS_INTERVAL_MS));
	}
	k_mutex_unlock(&stats_lock);
}

/* Stop the test and report why it ended. @p error is the interruption, or 0
 * for a host STOP: a continuous test only ends by STOP, so only a finite test
 * that is still running counts as interrupted (-ECANCELED). A failed stop
 * leaves the test in an unknown state and is reported as ERROR.
 */
static int stop_test(int error) {
	/* A completion racing this check is reported as interrupted; its work item
	 * then finds the state already STOPPED.
	 */
	bool cut_short = finite_test && radio_test_mode_is_running();
	int err = radio_test_mode_stop();

	stats_finish();
	if (err) {
		(void)client_state_change(CS_PROTOCOL_CLIENT_STATE_RUNNING, CS_PROTOCOL_CLIENT_STATE_ERROR,
		                          CS_PROTOCOL_REASON_INTERRUPTED, err);
		return err;
	}
	if (error == 0 && cut_short) {
		error = -ECANCELED;
	}
	(void)client_state_change(CS_PROTOCOL_CLIENT_STATE_RUNNING, CS_PROTOCOL_CLIENT_STATE_STOPPED,
	                          error ? CS_PROTOCOL_REASON_INTERRUPTED : CS_PROTOCOL_REASON_NONE,
	                          error);
	return 0;
}

static struct host_link_result stop(void) {
	int err = stop_test(0);

	return err ? HOST_LINK_RESULT_FAILED(err) : HOST_LINK_RESULT_OK;
}

static void interrupt(int error) {
	(void)stop_test(error);
}

/* No Bluetooth link in this build. A running test is left to STOP or
 * CLOSE_SESSION; the host sends no LINK_DISCONNECT in radio test mode.
 */
static struct host_link_result link_disconnect(void) {
	return HOST_LINK_RESULT_OK;
}

/* The applied test configuration spans host sessions; interrupt() has already
 * stopped a running test.
 */
static void session_changed(bool active) {
	client_state_session_changed(active);
}

static const struct host_link_handlers handlers = {
	.supported_modes = CS_PROTOCOL_MODE_BIT(CS_PROTOCOL_MODE_RADIO_TX_TEST),
	.firmware_version = APPVERSION,
	.client_state = get_state,
	.link_active = link_active,
	.validate_config = validate_config,
	.apply = apply,
	.start = start,
	.stop = stop,
	.interrupt = interrupt,
	.link_disconnect = link_disconnect,
	.session_changed = session_changed,
	.response_sent = response_sent,
};

int session_init(void) {
	return radio_test_mode_init();
}

const struct host_link_handlers *session_handlers(void) {
	return &handlers;
}

const char *session_build_name(void) {
	return "radio test";
}
```

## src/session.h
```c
/* SPDX-License-Identifier: MIT */
#ifndef SESSION_H_
#define SESSION_H_

#include "host_link/host_link_handlers.h"

/**
 * @file
 * @brief Operation-mode session of one build, behind the host link handlers.
 *
 * Implemented by cs_session.c in the Bluetooth build and by radio_session.c in
 * the radio test build.
 */

/**
 * @brief Prepare the radio for the build's modes. Starts no radio activity.
 * @return 0 or a negative error from the Bluetooth stack or radio test driver.
 */
int session_init(void);

/** @brief Handler table for host_link_init(). */
const struct host_link_handlers *session_handlers(void);

/** @brief Name of the build, for the boot log. */
const char *session_build_name(void);

#endif /* SESSION_H_ */
```
